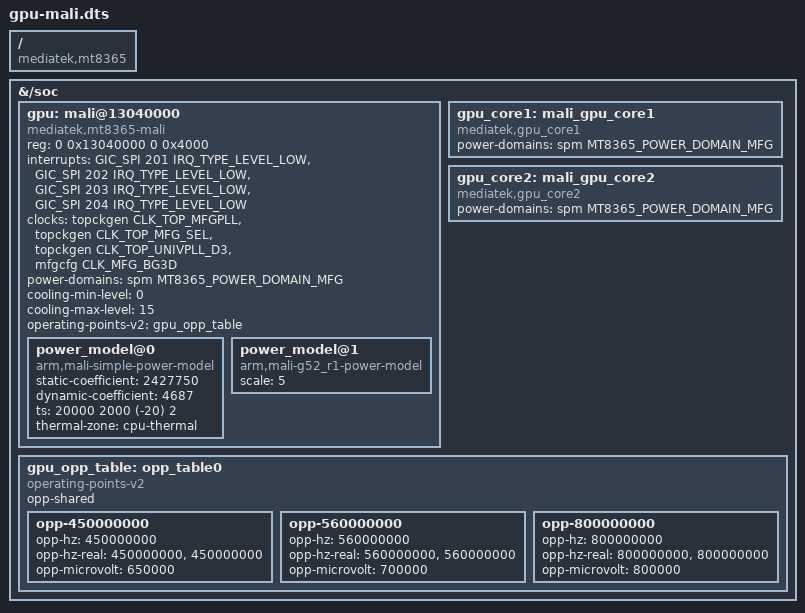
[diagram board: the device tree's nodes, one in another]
// SPDX-License-Identifier: (GPL-2.0 OR MIT)
/*
 * Copyright (c) 2021 MediaTek Inc.
 * Author: Macross Chen <macross.chen@mediatek.com>
 */

/dts-v1/;
/plugin/;
#include <dt-bindings/clock/mt8365-clk.h>
#include <dt-bindings/power/mt8365-power.h>
#include <dt-bindings/interrupt-controller/arm-gic.h>
#include <dt-bindings/interrupt-controller/irq.h>

/ {
	compatible = "mediatek,mt8365";

	fragment@0 {
		target-path = "/soc";
		__overlay__ {
			gpu: mali@13040000 {
				compatible = "mediatek,mt8365-mali", "arm,mali-bifrost", "arm,mali-midgard";
				reg = <0 0x13040000 0 0x4000>;
				interrupts =
					<GIC_SPI 201 IRQ_TYPE_LEVEL_LOW>,
					<GIC_SPI 202 IRQ_TYPE_LEVEL_LOW>,
					<GIC_SPI 203 IRQ_TYPE_LEVEL_LOW>,
					<GIC_SPI 204 IRQ_TYPE_LEVEL_LOW>;
				interrupt-names =
					"GPU",
					"MMU",
					"JOB",
					"EVENT";

				/*
				 * Note: the properties below are not part of the
				 * upstream binding.
				 */
				clocks =
					<&topckgen CLK_TOP_MFGPLL>,
					<&topckgen CLK_TOP_MFG_SEL>,
					<&topckgen CLK_TOP_UNIVPLL_D3>,
					<&mfgcfg CLK_MFG_BG3D>;
				clock-names =
					"clk_main_parent",
					"clk_mux",
					"clk_sub_parent",
					"subsys_mfg_cg";

				power-domains = <&spm MT8365_POWER_DOMAIN_MFG>;

				#cooling-cells = <2>;
				cooling-min-level = <0>;
				cooling-max-level = <15>;

				operating-points-v2 = <&gpu_opp_table>;

				power_model@0 {
					compatible = "arm,mali-simple-power-model";
					static-coefficient = <2427750>;
					dynamic-coefficient = <4687>;
					ts = <20000 2000 (-20) 2>;
					thermal-zone = "cpu-thermal";
				};
				power_model@1 {
					compatible = "arm,mali-g52_r1-power-model";
					scale = <5>;
				};
			};

			gpu_core1: mali_gpu_core1 {
				compatible = "mediatek,gpu_core1";
				power-domains = <&spm MT8365_POWER_DOMAIN_MFG>;
			};

			gpu_core2: mali_gpu_core2 {
				compatible = "mediatek,gpu_core2";
				power-domains = <&spm MT8365_POWER_DOMAIN_MFG>;
			};

			gpu_opp_table: opp_table0 {
				/*
				 * Note: "operating-points-v2-mali" compatible and the
				 * opp-core-mask properties are not part of upstream
				 * binding.
				 */

				compatible = "operating-points-v2", "operating-points-v2-mali";
				opp-shared;

				opp-450000000 {
					opp-hz = /bits/ 64 <450000000>;
					opp-hz-real = /bits/ 64 <450000000>,
							  /bits/ 64 <450000000>;
					opp-microvolt = <650000>;
				};
				opp-560000000 {
					opp-hz = /bits/ 64 <560000000>;
					opp-hz-real = /bits/ 64 <560000000>,
							  /bits/ 64 <560000000>;
					opp-microvolt = <700000>;
				};
				opp-800000000 {
					opp-hz = /bits/ 64 <800000000>;
					opp-hz-real = /bits/ 64 <800000000>,
							  /bits/ 64 <800000000>;
					opp-microvolt = <800000>;
				};
			};

		};
	};
};
